AUTOSAR XML (schema 4-2-2)
package /DBC_SysDesc_Can_Network/Pkg_Cluster
  can cluster Can_Network: protocol-name=CAN
    can physical channel Can_Network_Channel: comm-connectors=Conn_Can_Network_CANNODE_0_MCU
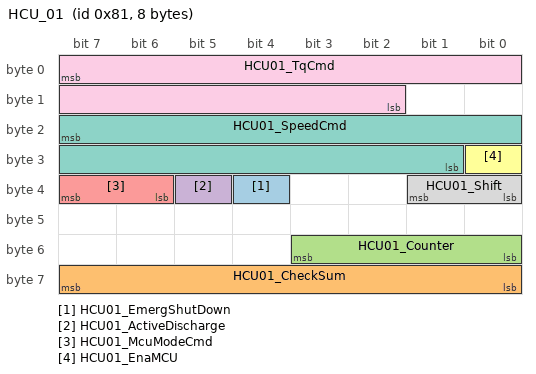
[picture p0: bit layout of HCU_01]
      frame HCU_01: id 0x81, to MCU, frame-length=8, can-addressing-mode=STANDARD, can-frame-rx-behavior=ANY
        carries pdu HCU_01: packing-byte-order=big-endian, start-position=7, update-indication-bit-position=-1
        pdu HCU_01: length=8, transmission-mode-false-timing=cyclic-timing={time-offset=0.0, time-period=0.01}, transmission-mode-true-timing=cyclic-timing={time-offset=0.0, time-period=0.01}
          transmission-mode-conditions:
            {data-filter={data-filter-type=ALWAYS, max=1, min=0, offset=0}, i-signal-in-i-pdu=HCU01_EmergShutDown}
            {data-filter={data-filter-type=ALWAYS, max=255, min=0, offset=0}, i-signal-in-i-pdu=HCU01_CheckSum}
            {data-filter={data-filter-type=ALWAYS, max=15, min=0, offset=0}, i-signal-in-i-pdu=HCU01_Counter}
            {data-filter={data-filter-type=ALWAYS, max=1, min=0, offset=0}, i-signal-in-i-pdu=HCU01_ActiveDischarge}
            {data-filter={data-filter-type=ALWAYS, max=3, min=0, offset=0}, i-signal-in-i-pdu=HCU01_McuModeCmd}
            {data-filter={data-filter-type=ALWAYS, max=1, min=0, offset=0}, i-signal-in-i-pdu=HCU01_EnaMCU}
            {data-filter={data-filter-type=NEW-IS-WITHIN, max=32767, min=0}, i-signal-in-i-pdu=HCU01_SpeedCmd}
            {data-filter={data-filter-type=ALWAYS, max=3, min=0, offset=0}, i-signal-in-i-pdu=HCU01_Shift}
            {data-filter={data-filter-type=NEW-IS-WITHIN, max=16383, min=0}, i-signal-in-i-pdu=HCU01_TqCmd}
          signal HCU01_EmergShutDown: start 36, 1 bit, big-endian, init-value=0, base-type=uint8, compu {raw=phys for phys 0..1, 0=FORBIDDING, 1=ALLOWING}, update-indication-bit-position=-1  # MCUÊ¹ÄÜÐÅºÅ "
          signal HCU01_CheckSum: start 63, 8 bit, big-endian, init-value=0, base-type=uint8, compu {raw=phys for phys 0..255}, update-indication-bit-position=-1, to MCU  # ¼ì²é "
          signal HCU01_Counter: start 51, 4 bit, big-endian, init-value=0, base-type=uint8, compu {raw=phys for phys 0..15}, update-indication-bit-position=-1, to MCU  # ¹öÂëÐÅÏ¢ "
          signal HCU01_ActiveDischarge: start 37, 1 bit, big-endian, init-value=0, base-type=uint8, compu {raw=phys for phys 0..1, 0=FORBIDDING, 1=ALLOWING}, update-indication-bit-position=-1, to MCU  # MCUÖ÷¶¯·Åµç "
          signal HCU01_McuModeCmd: start 39, 2 bit, big-endian, init-value=0, base-type=uint8, compu-method=CompuMethod_HCU01_McuModeCmd, update-indication-bit-position=-1, to MCU  # µç»ú¹¤×÷Ä£Ê½ÇëÇó "
          signal HCU01_EnaMCU: start 24, 1 bit, big-endian, init-value=0, base-type=uint8, compu {raw=phys for phys 0..1, 0=FORBIDDING, 1=ALLOWING}, update-indication-bit-position=-1, to MCU  # MCUÊ¹ÄÜÐÅºÅ "
          signal HCU01_SpeedCmd: start 23, 15 bit, big-endian, init-value=16384, base-type=uint16, compu {raw=phys+16384 for phys -16384..16383; unit rpm}, update-indication-bit-position=-1, to MCU  # ÐèÇó×ªËÙ "
          signal HCU01_Shift: start 33, 2 bit, big-endian, init-value=0, base-type=uint8, compu {raw=phys for phys 0..3, 0=N, 1=R, 2=D, 3=P}, update-indication-bit-position=-1, to MCU  # µ±Ç°Õû³µµµÎ»ÐÅÏ¢ "
          signal HCU01_TqCmd: start 7, 14 bit, big-endian, init-value=8192, base-type=uint16, compu {raw=phys*4+8192 for phys -2048..2047.75; unit Nm}, update-indication-bit-position=-1, to MCU  # HCU¶ÔMCUÅ¤¾ØÇëÇó"
      frame HCU_02: id 0x261, to MCU, frame-length=1, can-addressing-mode=STANDARD, can-frame-rx-behavior=ANY
        carries pdu HCU_02: packing-byte-order=big-endian, start-position=7, update-indication-bit-position=-1
        pdu HCU_02: length=1, transmission-mode-condition{data-filter={data-filter-type=ALWAYS, max=1, min=0, offset=0}, i-signal-in-i-pdu=HCU02_Poweroff}, transmission-mode-false-timing=cyclic-timing={time-offset=0.0, time-period=0.01}, transmission-mode-true-timing=cyclic-timing={time-offset=0.0, time-period=0.01}
          signal HCU02_Poweroff: start 6, 1 bit, big-endian, init-value=0, base-type=uint8, compu {raw=phys for phys 0..1, 0=NORMAL, 1=SLEEP}, update-indication-bit-position=-1, to MCU  # HCUµÍÑ¹ÏÂµç "
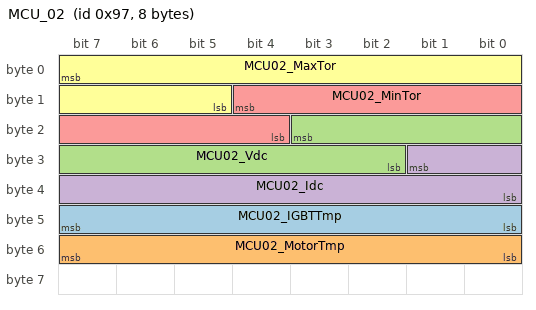
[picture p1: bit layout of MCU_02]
      frame MCU_02: id 0x97, from MCU, frame-length=8, can-addressing-mode=STANDARD
        carries pdu MCU_02: packing-byte-order=big-endian, start-position=7, update-indication-bit-position=-1
        pdu MCU_02: length=8, transmission-mode-false-timing=cyclic-timing={time-offset=0.0, time-period=0.05}, transmission-mode-true-timing=cyclic-timing={time-offset=0.0, time-period=0.05}
          transmission-mode-conditions:
            {data-filter={data-filter-type=ALWAYS, max=254, min=0}, i-signal-in-i-pdu=MCU02_IGBTTmp}
            {data-filter={data-filter-type=ALWAYS, max=254, min=0}, i-signal-in-i-pdu=MCU02_MotorTmp}
            {data-filter={data-filter-type=NEW-IS-WITHIN, max=1022, min=0, offset=0}, i-signal-in-i-pdu=MCU02_Vdc}
            {data-filter={data-filter-type=NEW-IS-WITHIN, max=1022, min=0}, i-signal-in-i-pdu=MCU02_Idc}
            {data-filter={data-filter-type=NEW-IS-WITHIN, max=510, min=0, offset=0}, i-signal-in-i-pdu=MCU02_MinTor}
            {data-filter={data-filter-type=NEW-IS-WITHIN, max=2046, min=0, offset=0}, i-signal-in-i-pdu=MCU02_MaxTor}
          signal MCU02_IGBTTmp: start 47, 8 bit, big-endian, init-value=40, base-type=uint8, compu {raw=phys+40 for phys -40..214; unit deg}, update-indication-bit-position=-1  # IGBTÎÂ¶È "
          signal MCU02_MotorTmp: start 55, 8 bit, big-endian, init-value=40, base-type=uint8, compu {raw=phys+40 for phys -40..214; unit deg}, update-indication-bit-position=-1  # µç»úÎÂ¶È "
          signal MCU02_Vdc: start 19, 10 bit, big-endian, init-value=0, base-type=uint16, compu {raw=phys for phys 0..1022; unit V}, update-indication-bit-position=-1  # Ä¸ÏßµçÑ¹ "
          signal MCU02_Idc: start 25, 10 bit, big-endian, init-value=511, base-type=uint16, compu {raw=phys+511 for phys -511..511; unit Ampere}, update-indication-bit-position=-1  # Ä¸ÏßµçÁ÷ "
          signal MCU02_MinTor: start 12, 9 bit, big-endian, init-value=0, base-type=uint16, compu {raw=phys for phys 0..510; unit Nm}, update-indication-bit-position=-1  # ×îÐ¡Å¤¾Ø "
          signal MCU02_MaxTor: start 7, 11 bit, big-endian, init-value=0, base-type=uint16, compu {raw=phys for phys 0..2046; unit Nm}, update-indication-bit-position=-1  # ×î´óÅ¤¾Ø "
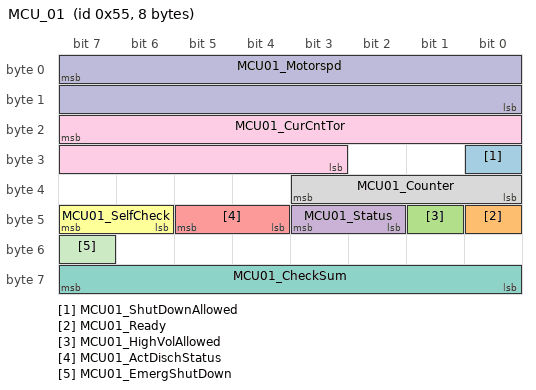
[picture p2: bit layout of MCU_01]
      frame MCU_01: id 0x55, from MCU, frame-length=8, can-addressing-mode=STANDARD
        carries pdu MCU_01: packing-byte-order=big-endian, start-position=7, update-indication-bit-position=-1
        pdu MCU_01: length=8, transmission-mode-false-timing=cyclic-timing={time-offset=0.0, time-period=0.01}, transmission-mode-true-timing=cyclic-timing={time-offset=0.0, time-period=0.01}
          transmission-mode-conditions:
            {data-filter={data-filter-type=ALWAYS, max=1, min=0, offset=0}, i-signal-in-i-pdu=MCU01_ShutDownAllowed}
            {data-filter={data-filter-type=ALWAYS, max=1, min=0, offset=0}, i-signal-in-i-pdu=MCU01_Ready}
            {data-filter={data-filter-type=ALWAYS, max=1, min=0, offset=0}, i-signal-in-i-pdu=MCU01_HighVolAllowed}
            {data-filter={data-filter-type=ALWAYS, max=3, min=0, offset=0}, i-signal-in-i-pdu=MCU01_Status}
            {data-filter={data-filter-type=ALWAYS, max=3, min=0, offset=0}, i-signal-in-i-pdu=MCU01_ActDischStatus}
            {data-filter={data-filter-type=ALWAYS, max=3, min=0, offset=0}, i-signal-in-i-pdu=MCU01_SelfCheck}
            {data-filter={data-filter-type=ALWAYS, max=254, min=0, offset=0}, i-signal-in-i-pdu=MCU01_CheckSum}
            {data-filter={data-filter-type=ALWAYS, max=3, min=0, offset=0}, i-signal-in-i-pdu=MCU01_Counter}
            {data-filter={data-filter-type=NEW-IS-WITHIN, max=8189, min=0}, i-signal-in-i-pdu=MCU01_CurCntTor}
            {data-filter={data-filter-type=NEW-IS-WITHIN, max=65534, min=0}, i-signal-in-i-pdu=MCU01_Motorspd}
            {data-filter={data-filter-type=ALWAYS, max=1, min=0, offset=0}, i-signal-in-i-pdu=MCU01_EmergShutDown}
          signal MCU01_ShutDownAllowed: start 24, 1 bit, big-endian, init-value=0, base-type=uint8, compu {raw=phys for phys 0..1, 0=FORBIDDING, 1=ALLOWING}, update-indication-bit-position=-1  # ÔÊÐíÏÂµç "
          signal MCU01_Ready: start 40, 1 bit, big-endian, init-value=0, base-type=uint8, compu-method=CompuMethod_MCU01_Ready, update-indication-bit-position=-1  # ¸ßÑ¹ÉÏµçÍê³É "
          signal MCU01_HighVolAllowed: start 41, 1 bit, big-endian, init-value=0, base-type=uint8, compu {raw=phys for phys 0..1, 0=FORBIDDINGTOTURNONHV, 1=ALLOWINGTOTURNONHV}, update-indication-bit-position=-1  # ÔÊÐí¸ßÑ¹ÉÏµç "
          signal MCU01_Status: start 43, 2 bit, big-endian, init-value=0, base-type=uint8, compu-method=CompuMethod_MCU01_Status, update-indication-bit-position=-1  # µç»ú¹¤×÷×´Ì¬ "
          signal MCU01_ActDischStatus: start 45, 2 bit, big-endian, init-value=0, base-type=uint8, compu-method=CompuMethod_MCU01_ActDischStatus, update-indication-bit-position=-1  # µç»ú¿ìËÙ·Åµç×´Ì¬ "
          signal MCU01_SelfCheck: start 47, 2 bit, big-endian, init-value=0, base-type=uint8, compu {raw=phys for phys 0..3, 0=DEFAULT, 1=SELFCHECKING, 2=OK, 3=FAILED}, update-indication-bit-position=-1  # MCU×Ô¼ì "
          signal MCU01_CheckSum: start 63, 8 bit, big-endian, init-value=0, base-type=uint8, compu {raw=phys for phys 0..254}, update-indication-bit-position=-1  # ±¨ÎÄchecksum "
          signal MCU01_Counter: start 35, 4 bit, big-endian, init-value=0, base-type=uint8, compu {raw=phys for phys 0..3}, update-indication-bit-position=-1  # ±¨ÎÄ¹öÂëÐÅÏ¢ "
          signal MCU01_CurCntTor: start 23, 13 bit, big-endian, init-value=4094, base-type=uint16, compu {raw=phys*2+4094 for phys -2047..2047.5; unit Nm}, update-indication-bit-position=-1  # µç»úµ±Ç°Å¤¾Ø "
          signal MCU01_Motorspd: start 7, 16 bit, big-endian, init-value=32767, base-type=uint16, compu {raw=phys+32767 for phys -32767..32767; unit rpm}, update-indication-bit-position=-1  # µç»úµ±Ç°×ªËÙ "
          signal MCU01_EmergShutDown: start 55, 1 bit, big-endian, init-value=0, base-type=uint8, compu {raw=phys for phys 0..1, 0=NORMAL, 1=EMERGSHUTDOWN}, update-indication-bit-position=-1  # ½ô¼±ÏÂµçÇëÇó "
      frame MCU_03: id 0x106, from MCU, frame-length=7, can-addressing-mode=STANDARD
        carries pdu MCU_03: packing-byte-order=big-endian, start-position=7, update-indication-bit-position=-1
        pdu MCU_03: length=7, transmission-mode-false-timing=cyclic-timing={time-offset=0.0, time-period=0.05}, transmission-mode-true-timing=cyclic-timing={time-offset=0.0, time-period=0.05}
          transmission-mode-conditions:
            {data-filter={data-filter-type=ALWAYS, max=1, min=0, offset=0}, i-signal-in-i-pdu=MCU03_LI_OverSpeed}
            {data-filter={data-filter-type=ALWAYS, max=1, min=0, offset=0}, i-signal-in-i-pdu=MCU03_LI_OverTempEM}
            {data-filter={data-filter-type=ALWAYS, max=1, min=0, offset=0}, i-signal-in-i-pdu=MCU03_LI_OverTempINV}
            {data-filter={data-filter-type=ALWAYS, max=1, min=0, offset=0}, i-signal-in-i-pdu=MCU03_LI_UdcUnder}
            {data-filter={data-filter-type=ALWAYS, max=1, min=0, offset=0}, i-signal-in-i-pdu=MCU03_LI_UdcOver}
            {data-filter={data-filter-type=ALWAYS, max=1, min=0, offset=0}, i-signal-in-i-pdu=MCU03_RF_PhaseImp}
            {data-filter={data-filter-type=ALWAYS, max=1, min=0, offset=0}, i-signal-in-i-pdu=MCU03_12VSupply}
            {data-filter={data-filter-type=ALWAYS, max=1, min=0, offset=0}, i-signal-in-i-pdu=MCU03_RF_PhCOver}
            {data-filter={data-filter-type=ALWAYS, max=1, min=0, offset=0}, i-signal-in-i-pdu=MCU03_RF_PhBOver}
            {data-filter={data-filter-type=ALWAYS, max=1, min=0, offset=0}, i-signal-in-i-pdu=MCU03_RF_PhAOver}
            {data-filter={data-filter-type=ALWAYS, max=1, min=0, offset=0}, i-signal-in-i-pdu=MCU03_RF_OverSpeed}
            {data-filter={data-filter-type=ALWAYS, max=1, min=0, offset=0}, i-signal-in-i-pdu=MCU03_RF_MsgTO}
            {data-filter={data-filter-type=ALWAYS, max=1, min=0, offset=0}, i-signal-in-i-pdu=MCU03_RF_OverTempEM}
            {data-filter={data-filter-type=ALWAYS, max=1, min=0, offset=0}, i-signal-in-i-pdu=MCU03_RF_OverTempINV}
            {data-filter={data-filter-type=ALWAYS, max=1, min=0, offset=0}, i-signal-in-i-pdu=MCU03_RF_IntError}
            {data-filter={data-filter-type=ALWAYS, max=1, min=0, offset=0}, i-signal-in-i-pdu=MCU03_RF_HWOverCur}
            {data-filter={data-filter-type=ALWAYS, max=1, min=0, offset=0}, i-signal-in-i-pdu=MCU03_RF_UDCUnder}
            {data-filter={data-filter-type=ALWAYS, max=1, min=0, offset=0}, i-signal-in-i-pdu=MCU03_RF_UdcOver}
            {data-filter={data-filter-type=ALWAYS, max=1, min=0, offset=0}, i-signal-in-i-pdu=MCU03_RF_IdcOver}
            {data-filter={data-filter-type=ALWAYS, max=1, min=0, offset=0}, i-signal-in-i-pdu=MCU03_RF_ToqError}
            {data-filter={data-filter-type=ALWAYS, max=1, min=0, offset=0}, i-signal-in-i-pdu=MCU03_RF_BusOff}
            {data-filter={data-filter-type=ALWAYS, max=1, min=0, offset=0}, i-signal-in-i-pdu=MCU03_NRF_SysFailure}
            {data-filter={data-filter-type=ALWAYS, max=1, min=0, offset=0}, i-signal-in-i-pdu=MCU03_NRF_Resolver}
            {data-filter={data-filter-type=ALWAYS, max=1, min=0, offset=0}, i-signal-in-i-pdu=MCU03_NRF_PhCSamp}
            {data-filter={data-filter-type=ALWAYS, max=1, min=0, offset=0}, i-signal-in-i-pdu=MCU03_NRF_PhBSamp}
            {data-filter={data-filter-type=ALWAYS, max=1, min=0, offset=0}, i-signal-in-i-pdu=MCU03_NRF_InvTempSamp}
            {data-filter={data-filter-type=ALWAYS, max=1, min=0, offset=0}, i-signal-in-i-pdu=MCU03_NRF_PhASamp}
            {data-filter={data-filter-type=ALWAYS, max=1, min=0, offset=0}, i-signal-in-i-pdu=MCU03_NRF_DESAT}
            {data-filter={data-filter-type=ALWAYS, max=1, min=0, offset=0}, i-signal-in-i-pdu=MCU03_NRF_UdcSamp}
            {data-filter={data-filter-type=ALWAYS, max=1, min=0, offset=0}, i-signal-in-i-pdu=MCU03_NRF_COMError}
            {data-filter={data-filter-type=ALWAYS, max=1, min=0, offset=0}, i-signal-in-i-pdu=MCU03_NRF_5VSupply}
            {data-filter={data-filter-type=ALWAYS, max=1, min=0, offset=0}, i-signal-in-i-pdu=MCU03_NRF_EMTempSamp}
            {data-filter={data-filter-type=ALWAYS, max=1, min=0, offset=0}, i-signal-in-i-pdu=MCU03_NRF_IdcSamp}
          signal MCU03_LI_OverSpeed: start 51, 1 bit, big-endian, init-value=0, base-type=uint8, compu {raw=phys for phys 0..1, 0=NOTROUBLE, 1=TROUBLE}, update-indication-bit-position=-1  # ³¬ËÙ "
          signal MCU03_LI_OverTempEM: start 50, 1 bit, big-endian, init-value=0, base-type=uint8, compu {raw=phys for phys 0..1, 0=NOTROUBLE, 1=TROUBLE}, update-indication-bit-position=-1  # µç»ú¶¨×Ó¹ýÎÂ "
          signal MCU03_LI_OverTempINV: start 49, 1 bit, big-endian, init-value=0, base-type=uint8, compu {raw=phys for phys 0..1, 0=NOTROUBLE, 1=TROUBLE}, update-indication-bit-position=-1  # Äæ±äÆ÷¹ýÎÂ "
          signal MCU03_LI_UdcUnder: start 48, 1 bit, big-endian, init-value=0, base-type=uint8, compu {raw=phys for phys 0..1, 0=NOTROUBLE, 1=TROUBLE}, update-indication-bit-position=-1  # Ä¸ÏßÇ·Ñ¹ "
          signal MCU03_LI_UdcOver: start 52, 1 bit, big-endian, init-value=0, base-type=uint8, compu {raw=phys for phys 0..1, 0=NOTROUBLE, 1=TROUBLE}, update-indication-bit-position=-1  # Ä¸Ïß¹ýÑ¹ "
          signal MCU03_RF_PhaseImp: start 39, 1 bit, big-endian, init-value=0, base-type=uint8, compu {raw=phys for phys 0..1, 0=NOTROUBLE, 1=TROUBLE}, update-indication-bit-position=-1  # ÈýÏàµçÁ÷²»Æ½ºâ "
          signal MCU03_12VSupply: start 32, 1 bit, big-endian, init-value=0, base-type=uint8, compu {raw=phys for phys 0..1, 0=NOTROUBLE, 1=TROUBLE}, update-indication-bit-position=-1  # ÈõµçµçÔ´¹ÊÕÏ "
          signal MCU03_RF_PhCOver: start 47, 1 bit, big-endian, init-value=0, base-type=uint8, compu {raw=phys for phys 0..1, 0=NOTROUBLE, 1=TROUBLE}, update-indication-bit-position=-1  # CÏà¹ýÁ÷ "
          signal MCU03_RF_PhBOver: start 46, 1 bit, big-endian, init-value=0, base-type=uint8, compu {raw=phys for phys 0..1, 0=NOTROUBLE, 1=TROUBLE}, update-indication-bit-position=-1  # BÏà¹ýÁ÷ "
          signal MCU03_RF_PhAOver: start 45, 1 bit, big-endian, init-value=0, base-type=uint8, compu {raw=phys for phys 0..1, 0=NOTROUBLE, 1=TROUBLE}, update-indication-bit-position=-1  # AÏà¹ýÁ÷ "
          signal MCU03_RF_OverSpeed: start 41, 1 bit, big-endian, init-value=0, base-type=uint8, compu {raw=phys for phys 0..1, 0=NOTROUBLE, 1=TROUBLE}, update-indication-bit-position=-1  # µç»ú¹ýËÙ "
          signal MCU03_RF_MsgTO: start 43, 1 bit, big-endian, init-value=0, base-type=uint8, compu {raw=phys for phys 0..1, 0=NOTROUBLE, 1=TROUBLE}, update-indication-bit-position=-1  # ÏûÏ¢¶ªÊ§ "
          signal MCU03_RF_OverTempEM: start 40, 1 bit, big-endian, init-value=0, base-type=uint8, compu {raw=phys for phys 0..1, 0=NOTROUBLE, 1=TROUBLE}, update-indication-bit-position=-1  # ¶¨×ÓÈÆ×é¹ýÎÂ "
          signal MCU03_RF_OverTempINV: start 36, 1 bit, big-endian, init-value=0, base-type=uint8, compu {raw=phys for phys 0..1, 0=NOTROUBLE, 1=TROUBLE}, update-indication-bit-position=-1  # Äæ±äÆ÷¹ýÎÂ "
          signal MCU03_RF_IntError: start 38, 1 bit, big-endian, init-value=0, base-type=uint8, compu {raw=phys for phys 0..1, 0=NOTROUBLE, 1=TROUBLE}, update-indication-bit-position=-1  # ³ÌÐò³¬Ê± "
          signal MCU03_RF_HWOverCur: start 44, 1 bit, big-endian, init-value=0, base-type=uint8, compu {raw=phys for phys 0..1, 0=NOTROUBLE, 1=TROUBLE}, update-indication-bit-position=-1  # ÏàµçÁ÷Ó²¼þ¼ì²â¹ýÁ÷ "
          signal MCU03_RF_UDCUnder: start 37, 1 bit, big-endian, init-value=0, base-type=uint8, compu {raw=phys for phys 0..1, 0=NOTROUBLE, 1=TROUBLE}, update-indication-bit-position=-1  # Ä¸ÏßÇ·Ñ¹ "
          signal MCU03_RF_UdcOver: start 34, 1 bit, big-endian, init-value=0, base-type=uint8, compu {raw=phys for phys 0..1, 0=NOTROUBLE, 1=TROUBLE}, update-indication-bit-position=-1  # Ä¸Ïß¹ýÑ¹ "
          signal MCU03_RF_IdcOver: start 33, 1 bit, big-endian, init-value=0, base-type=uint8, compu {raw=phys for phys 0..1, 0=NOTROUBLE, 1=TROUBLE}, update-indication-bit-position=-1  # Ä¸Ïß¹ýÁ÷ "
          signal MCU03_RF_ToqError: start 35, 1 bit, big-endian, init-value=0, base-type=uint8, compu {raw=phys for phys 0..1, 0=NOTROUBLE, 1=TROUBLE}, update-indication-bit-position=-1  # Á¦¾ØÊä³öÒì³£ "
          signal MCU03_RF_BusOff: start 42, 1 bit, big-endian, init-value=0, base-type=uint8, compu {raw=phys for phys 0..1, 0=NOTROUBLE, 1=TROUBLE}, update-indication-bit-position=-1  # CAN×ÜÏßÍ¨ÐÅÖÐ¶Ï "
          signal MCU03_NRF_SysFailure: start 11, 1 bit, big-endian, init-value=0, base-type=uint8, compu {raw=phys for phys 0..1, 0=NOTROUBLE, 1=TROUBLE}, update-indication-bit-position=-1  # ÏµÍ³Òì³£ "
          signal MCU03_NRF_Resolver: start 2, 1 bit, big-endian, init-value=0, base-type=uint8, compu {raw=phys for phys 0..1, 0=NOTROUBLE, 1=TROUBLE}, update-indication-bit-position=-1  # Ðý±ä½âÎö¹ÊÕÏ "
          signal MCU03_NRF_PhCSamp: start 5, 1 bit, big-endian, init-value=0, base-type=uint8, compu {raw=phys for phys 0..1, 0=NOTROUBLE, 1=TROUBLE}, update-indication-bit-position=-1  # CÏàµçÁ÷²ÉÑù¹ÊÕÏ "
          signal MCU03_NRF_PhBSamp: start 4, 1 bit, big-endian, init-value=0, base-type=uint8, compu {raw=phys for phys 0..1, 0=NOTROUBLE, 1=TROUBLE}, update-indication-bit-position=-1  # BÏàµçÁ÷²ÉÑù¹ÊÕÏ "
          signal MCU03_NRF_InvTempSamp: start 9, 1 bit, big-endian, init-value=0, base-type=uint8, compu {raw=phys for phys 0..1, 0=NOTROUBLE, 1=TROUBLE}, update-indication-bit-position=-1  # Äæ±äÆ÷ÎÂ¶È²ÉÑù¹ÊÕÏ "
          signal MCU03_NRF_PhASamp: start 3, 1 bit, big-endian, init-value=0, base-type=uint8, compu {raw=phys for phys 0..1, 0=NOTROUBLE, 1=TROUBLE}, update-indication-bit-position=-1  # AÏàµçÁ÷²ÉÑù¹ÊÕÏ "
          signal MCU03_NRF_DESAT: start 0, 1 bit, big-endian, init-value=0, base-type=uint8, compu {raw=phys for phys 0..1, 0=NOTROUBLE, 1=TROUBLE}, update-indication-bit-position=-1  # IGBTÍË±¥ºÍ¹ÊÕÏ "
          signal MCU03_NRF_UdcSamp: start 8, 1 bit, big-endian, init-value=0, base-type=uint8, compu {raw=phys for phys 0..1, 0=NOTROUBLE, 1=TROUBLE}, update-indication-bit-position=-1  # Ä¸ÏßµçÑ¹²ÉÑù¹ÊÕÏ "
          signal MCU03_NRF_COMError: start 10, 1 bit, big-endian, init-value=0, base-type=uint8, compu {raw=phys for phys 0..1, 0=NOTROUBLE, 1=TROUBLE}, update-indication-bit-position=-1  # Í¨Ñ¶Ä£¿é¹ÊÕÏ "
          signal MCU03_NRF_5VSupply: start 1, 1 bit, big-endian, init-value=0, base-type=uint8, compu {raw=phys for phys 0..1, 0=NOTROUBLE, 1=TROUBLE}, update-indication-bit-position=-1  # Ä£Äâ5VµçÔ´¹ÊÕÏ "
          signal MCU03_NRF_EMTempSamp: start 6, 1 bit, big-endian, init-value=0, base-type=uint8, compu {raw=phys for phys 0..1, 0=NOTROUBLE, 1=TROUBLE}, update-indication-bit-position=-1  # µç»úÎÂ¶È²ÉÑù¹ÊÕÏ "
          signal MCU03_NRF_IdcSamp: start 15, 1 bit, big-endian, init-value=0, base-type=uint8, compu {raw=phys for phys 0..1, 0=NOTROUBLE, 1=TROUBLE}, update-indication-bit-position=-1  # Ä¸ÏßµçÁ÷²ÉÑù¹ÊÕÏ "
      frame Diag_Functional_request: id 0x7DF, to MCU, frame-length=8, can-addressing-mode=STANDARD, can-fd-frame-support=true, can-frame-rx-behavior=CAN-FD
        carries pdu Diag_Functional_request: start-position=7, update-indication-bit-position=-1
        dcm i pdu Diag_Functional_request: length=8
      frame Diag_Physical_request: id 0x740, to MCU, frame-length=8, can-addressing-mode=STANDARD, can-fd-frame-support=true, can-frame-rx-behavior=CAN-FD
        carries pdu Diag_Physical_request: start-position=7, update-indication-bit-position=-1
        dcm i pdu Diag_Physical_request: length=8
      frame Diag_Physical_response: id 0x748, from MCU, frame-length=8, can-addressing-mode=STANDARD, can-fd-frame-support=true, can-frame-tx-behavior=CAN-FD
        carries pdu Diag_Physical_response: start-position=7, update-indication-bit-position=-1
        dcm i pdu Diag_Physical_response: length=8
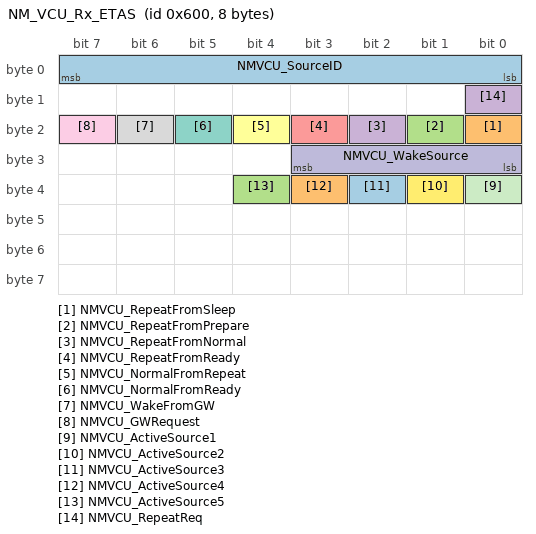
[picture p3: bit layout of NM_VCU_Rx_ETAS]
      frame NM_VCU_Rx_ETAS: id 0x600, to MCU, frame-length=8, can-addressing-mode=STANDARD, can-frame-rx-behavior=ANY
        carries pdu NM_VCU_Rx_ETAS: packing-byte-order=big-endian, start-position=7, update-indication-bit-position=-1
        nm pdu NM_VCU_Rx_ETAS: length=8, nm-data-information=false, nm-vote-information=false
          signal NMVCU_SourceID: start 7, 8 bit, big-endian, init-value=0, base-type=uint8, compu {raw=phys for phys 0..255}, update-indication-bit-position=-1, to MCU  # The source node id"
          signal NMVCU_RepeatFromSleep: start 16, 1 bit, big-endian, init-value=0, base-type=uint8, compu {raw=phys for phys 0..1, 0=NOTOCCUR, 1=OCCUR}, update-indication-bit-position=-1, to MCU
          signal NMVCU_RepeatFromPrepare: start 17, 1 bit, big-endian, init-value=0, base-type=uint8, compu {raw=phys for phys 0..1, 0=NOTOCCUR, 1=OCCUR}, update-indication-bit-position=-1, to MCU
          signal NMVCU_RepeatFromNormal: start 18, 1 bit, big-endian, init-value=0, base-type=uint8, compu {raw=phys for phys 0..1, 0=NOTOCCUR, 1=OCCUR}, update-indication-bit-position=-1, to MCU
          signal NMVCU_RepeatFromReady: start 19, 1 bit, big-endian, init-value=0, base-type=uint8, compu {raw=phys for phys 0..1, 0=NOTOCCUR, 1=OCCUR}, update-indication-bit-position=-1, to MCU
          signal NMVCU_NormalFromRepeat: start 20, 1 bit, big-endian, init-value=0, base-type=uint8, compu {raw=phys for phys 0..1, 0=NOTOCCUR, 1=OCCUR}, update-indication-bit-position=-1, to MCU
          signal NMVCU_NormalFromReady: start 21, 1 bit, big-endian, init-value=0, base-type=uint8, compu {raw=phys for phys 0..1, 0=NOTOCCUR, 1=OCCUR}, update-indication-bit-position=-1, to MCU
          signal NMVCU_WakeFromGW: start 22, 1 bit, big-endian, init-value=0, base-type=uint8, compu {raw=phys for phys 0..1, 0=NOTOCCUR, 1=OCCUR}, update-indication-bit-position=-1, to MCU
          signal NMVCU_GWRequest: start 23, 1 bit, big-endian, init-value=0, base-type=uint8, compu {raw=phys for phys 0..1, 0=NOTREQUEST, 1=REQUEST}, update-indication-bit-position=-1, to MCU
          signal NMVCU_WakeSource: start 27, 4 bit, big-endian, init-value=0, base-type=uint8, compu {raw=phys for phys 0..15, 0=CANWAKEUP, 1=KL_15}, update-indication-bit-position=-1, to MCU  # The wakeup source"
          signal NMVCU_ActiveSource1: start 32, 1 bit, big-endian, init-value=0, base-type=uint8, compu {raw=phys for phys 0..1, 0=NOTACTIVE, 1=KL15}, update-indication-bit-position=-1, to MCU  # The NM active sorce is KL15"
          signal NMVCU_ActiveSource2: start 33, 1 bit, big-endian, init-value=0, base-type=uint8, compu {raw=phys for phys 0..1, 0=NOTACTIVE, 1=DIAGNOSE}, update-indication-bit-position=-1, to MCU  # The NM active sorce is Diagnose"
          signal NMVCU_ActiveSource3: start 34, 1 bit, big-endian, init-value=0, base-type=uint8, compu {raw=phys for phys 0..1, 0=NOTACTIVE, 1=REPEATMESSAGETIMERHASNOTEXPIRED}, update-indication-bit-position=-1, to MCU  # The NM active sorce is Repeat message timer has not expired"
          signal NMVCU_ActiveSource4: start 35, 1 bit, big-endian, init-value=0, base-type=uint8, compu {raw=phys for phys 0..1, 0=NOTACTIVE, 1=ACCHARGING}, update-indication-bit-position=-1, to MCU  # The NM active sorce is AC Charging"
          signal NMVCU_ActiveSource5: start 36, 1 bit, big-endian, init-value=0, base-type=uint8, compu {raw=phys for phys 0..1, 0=NOTACTIVE, 1=DCCHARGING}, update-indication-bit-position=-1, to MCU  # The NM active sorce is DC Charging"
          signal NMVCU_RepeatReq: start 8, 1 bit, big-endian, init-value=0, base-type=uint8, compu {raw=phys for phys 0..1, 0=NOTREQUEST, 1=REQUEST}, update-indication-bit-position=-1, to MCU  # The repeat message request"
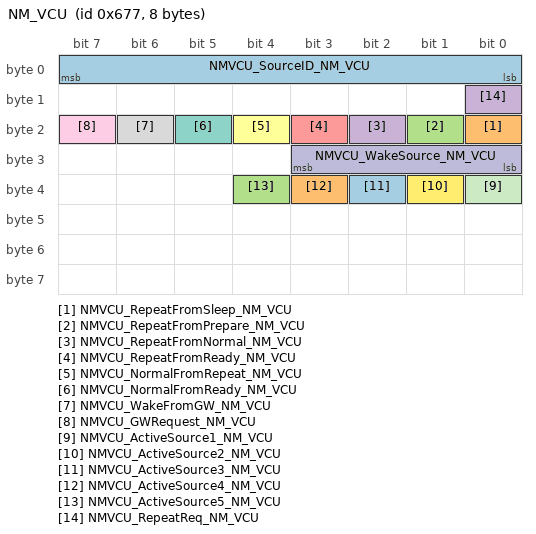
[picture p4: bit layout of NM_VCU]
      frame NM_VCU: id 0x677, from MCU, frame-length=8, can-addressing-mode=STANDARD
        carries pdu NM_VCU: packing-byte-order=big-endian, start-position=7, update-indication-bit-position=-1
        nm pdu NM_VCU: length=8, nm-data-information=false, nm-vote-information=false
          signal NMVCU_SourceID_NM_VCU: start 7, 8 bit, big-endian, init-value=0, base-type=uint8, compu {raw=phys for phys 0..255}, update-indication-bit-position=-1  # The source node id"
          signal NMVCU_RepeatFromSleep_NM_VCU: start 16, 1 bit, big-endian, init-value=0, base-type=uint8, compu {raw=phys for phys 0..1, 0=NOTOCCUR, 1=OCCUR}, update-indication-bit-position=-1
          signal NMVCU_RepeatFromPrepare_NM_VCU: start 17, 1 bit, big-endian, init-value=0, base-type=uint8, compu {raw=phys for phys 0..1, 0=NOTOCCUR, 1=OCCUR}, update-indication-bit-position=-1
          signal NMVCU_RepeatFromNormal_NM_VCU: start 18, 1 bit, big-endian, init-value=0, base-type=uint8, compu {raw=phys for phys 0..1, 0=NOTOCCUR, 1=OCCUR}, update-indication-bit-position=-1
          signal NMVCU_RepeatFromReady_NM_VCU: start 19, 1 bit, big-endian, init-value=0, base-type=uint8, compu {raw=phys for phys 0..1, 0=NOTOCCUR, 1=OCCUR}, update-indication-bit-position=-1
          signal NMVCU_NormalFromRepeat_NM_VCU: start 20, 1 bit, big-endian, init-value=0, base-type=uint8, compu {raw=phys for phys 0..1, 0=NOTOCCUR, 1=OCCUR}, update-indication-bit-position=-1
          signal NMVCU_NormalFromReady_NM_VCU: start 21, 1 bit, big-endian, init-value=0, base-type=uint8, compu {raw=phys for phys 0..1, 0=NOTOCCUR, 1=OCCUR}, update-indication-bit-position=-1
          signal NMVCU_WakeFromGW_NM_VCU: start 22, 1 bit, big-endian, init-value=0, base-type=uint8, compu {raw=phys for phys 0..1, 0=NOTOCCUR, 1=OCCUR}, update-indication-bit-position=-1
          signal NMVCU_GWRequest_NM_VCU: start 23, 1 bit, big-endian, init-value=0, base-type=uint8, compu {raw=phys for phys 0..1, 0=NOTREQUEST, 1=REQUEST}, update-indication-bit-position=-1
          signal NMVCU_WakeSource_NM_VCU: start 27, 4 bit, big-endian, init-value=0, base-type=uint8, compu {raw=phys for phys 0..15, 0=CANWAKEUP, 1=KL_15}, update-indication-bit-position=-1  # The wakeup source"
          signal NMVCU_ActiveSource1_NM_VCU: start 32, 1 bit, big-endian, init-value=0, base-type=uint8, compu {raw=phys for phys 0..1, 0=NOTACTIVE, 1=KL15}, update-indication-bit-position=-1  # The NM active sorce is KL15"
          signal NMVCU_ActiveSource2_NM_VCU: start 33, 1 bit, big-endian, init-value=0, base-type=uint8, compu {raw=phys for phys 0..1, 0=NOTACTIVE, 1=DIAGNOSE}, update-indication-bit-position=-1  # The NM active sorce is Diagnose"
          signal NMVCU_ActiveSource3_NM_VCU: start 34, 1 bit, big-endian, init-value=0, base-type=uint8, compu {raw=phys for phys 0..1, 0=NOTACTIVE, 1=REPEATMESSAGETIMERHASNOTEXPIRED}, update-indication-bit-position=-1  # The NM active sorce is Repeat message timer has not expired"
          signal NMVCU_ActiveSource4_NM_VCU: start 35, 1 bit, big-endian, init-value=0, base-type=uint8, compu {raw=phys for phys 0..1, 0=NOTACTIVE, 1=ACCHARGING}, update-indication-bit-position=-1  # The NM active sorce is AC Charging"
          signal NMVCU_ActiveSource5_NM_VCU: start 36, 1 bit, big-endian, init-value=0, base-type=uint8, compu {raw=phys for phys 0..1, 0=NOTACTIVE, 1=DCCHARGING}, update-indication-bit-position=-1  # The NM active sorce is DC Charging"
          signal NMVCU_RepeatReq_NM_VCU: start 8, 1 bit, big-endian, init-value=0, base-type=uint8, compu {raw=phys for phys 0..1, 0=NOTREQUEST, 1=REQUEST}, update-indication-bit-position=-1  # The repeat message request"
      frame HCU_03: id 0x266, to MCU, frame-length=1, can-addressing-mode=STANDARD, can-frame-rx-behavior=ANY
        carries pdu HCU_03: packing-byte-order=big-endian, start-position=7, update-indication-bit-position=-1
        pdu HCU_03: length=1, transmission-mode-condition{data-filter={data-filter-type=ALWAYS, max=1, min=0, offset=0}, i-signal-in-i-pdu=HCU03_Poweroff}, transmission-mode-false-timing=cyclic-timing={time-offset=0.0, time-period=0.01}, transmission-mode-true-timing=cyclic-timing={time-offset=0.0, time-period=0.01}
          signal HCU03_Poweroff: start 0, 1 bit, big-endian, init-value=0, base-type=uint8, compu {raw=phys for phys 0..1, 0=NORMAL, 1=SLEEP}, update-indication-bit-position=-1, to MCU  # ghh"
      frame HCU_04: id 0x277, to MCU, frame-length=1, can-addressing-mode=STANDARD, can-frame-rx-behavior=ANY
        carries pdu HCU_04: packing-byte-order=big-endian, start-position=7, update-indication-bit-position=-1
        pdu HCU_04: length=1, transmission-mode-condition{data-filter={data-filter-type=ALWAYS, max=1, min=0, offset=0}, i-signal-in-i-pdu=HCU04_Poweroff}, transmission-mode-false-timing=cyclic-timing={time-offset=0.0, time-period=0.01}, transmission-mode-true-timing=cyclic-timing={time-offset=0.0, time-period=0.01}
          signal HCU04_Poweroff: start 0, 1 bit, big-endian, init-value=0, base-type=uint8, compu {raw=phys for phys 0..1, 0=NORMAL, 1=SLEEP}, update-indication-bit-position=-1, to MCU  # ghh"
      frame HCU_05: id 0x288, to MCU, frame-length=1, can-addressing-mode=STANDARD, can-frame-rx-behavior=ANY
        carries pdu HCU_05: packing-byte-order=big-endian, start-position=7, update-indication-bit-position=-1
        pdu HCU_05: length=1, transmission-mode-condition{data-filter={data-filter-type=ALWAYS, max=1, min=0, offset=0}, i-signal-in-i-pdu=HCU05_Poweroff}, transmission-mode-false-timing=cyclic-timing={time-offset=0.0, time-period=0.01}, transmission-mode-true-timing=cyclic-timing={time-offset=0.0, time-period=0.01}
          signal HCU05_Poweroff: start 0, 1 bit, big-endian, init-value=0, base-type=uint8, compu {raw=phys for phys 0..1, 0=NORMAL, 1=SLEEP}, update-indication-bit-position=-1, to MCU  # ghh"
      frame MCU_04: id 0x108, from MCU, frame-length=8, can-addressing-mode=STANDARD
        carries pdu MCU_04: packing-byte-order=big-endian, start-position=7, update-indication-bit-position=-1
        pdu MCU_04: length=8, transmission-mode-condition{data-filter={data-filter-type=ALWAYS, max=1, min=0, offset=0}, i-signal-in-i-pdu=MCU04_Test}, transmission-mode-false-timing=cyclic-timing={time-offset=0.0, time-period=0.05}, transmission-mode-true-timing=cyclic-timing={time-offset=0.0, time-period=0.05}
          signal MCU04_Test: start 15, 1 bit, big-endian, init-value=0, base-type=uint8, compu {raw=phys for phys 0..1, 0=NOTROUBLE, 1=TROUBLE}, update-indication-bit-position=-1  # Ä¸ÏßµçÁ÷²ÉÑù¹ÊÕÏ "
  can cluster Can_Network_XCP: protocol-name=CAN
    can physical channel Can_Network_XCP_Channel: comm-connectors=Conn_Can_Network_CANNODE_1_MCU
      frame XCP_RX_CMD: id 0x333, to MCU, frame-length=8, can-addressing-mode=STANDARD, can-frame-rx-behavior=ANY
        carries pdu XCP_RX_CMD: start-position=7, update-indication-bit-position=-1
        xcp pdu XCP_RX_CMD: length=8
      frame XCP_TX_RES: id 0x777, from MCU, frame-length=8, can-addressing-mode=STANDARD
        carries pdu XCP_TX_RES: start-position=7, update-indication-bit-position=-1
        xcp pdu XCP_TX_RES: length=8
      frame XCP_RX_Broadcast: id 0x332, to MCU, frame-length=8, can-addressing-mode=STANDARD, can-frame-rx-behavior=ANY
        carries pdu XCP_RX_Broadcast: start-position=7, update-indication-bit-position=-1
        xcp pdu XCP_RX_Broadcast: length=8
      frame XCP_TX_DAQ2: id 0x77A, from MCU, frame-length=8, can-addressing-mode=STANDARD
        carries pdu XCP_TX_DAQ2: start-position=7, update-indication-bit-position=-1
        xcp pdu XCP_TX_DAQ2: length=8
      frame XCP_TX_DAQ1: id 0x779, from MCU, frame-length=8, can-addressing-mode=STANDARD
        carries pdu XCP_TX_DAQ1: start-position=7, update-indication-bit-position=-1
        xcp pdu XCP_TX_DAQ1: length=8
      frame XCP_TX_DAQ0: id 0x778, from MCU, frame-length=8, can-addressing-mode=STANDARD
        carries pdu XCP_TX_DAQ0: start-position=7, update-indication-bit-position=-1
        xcp pdu XCP_TX_DAQ0: length=8
package /DBC_SysDesc_Can_Network/Pkg_Ecu
  ecu instance MCU: com-configuration-gw-time-base=0.005, com-configuration-rx-time-base=0.01, com-configuration-tx-time-base=0.01, sleep-mode-supported=false, wake-up-over-bus-supported=false
    can communication controller Can_Network_CANNODE_0: can-controller-attributes=can-controller-configuration={prop-seg=0, sync-jump-width=0, time-seg-1=10, time-seg-2=0}
    can communication controller Can_Network_CANNODE_1: can-controller-attributes=can-controller-configuration={prop-seg=1, sync-jump-width=1, time-seg-1=3, time-seg-2=3}
    can communication connector Conn_Can_Network_CANNODE_0_MCU: comm-controller=Can_Network_CANNODE_0
    can communication connector Conn_Can_Network_CANNODE_1_MCU: comm-controller=Can_Network_CANNODE_1
package /DBC_SysDesc_Can_Network/Pkg_CompuMethod
  compu method CompuMethod_MCU01_Ready: raw=phys for phys 0..1, 0=FORBIDDINGGETTINGTORQUECMD, 1=ALLOWMCUTOGETTORQUECOMMAND
  compu method CompuMethod_MCU01_Status: raw=phys for phys 0..3, 0=NORMAL, 1=WARNING_DERATING, 2=RECOVERABLEFAULT, 3=NORECOVERABLEFAULT
  compu method CompuMethod_MCU01_ActDischStatus: raw=phys for phys 0..3, 0=DEFAULT, 1=DISCHARGING, 2=DISCHARGEFINISHED, 3=RESERVED
  compu method CompuMethod_HCU01_McuModeCmd: raw=phys for phys 0..3, 0=DEFAULT, 1=TORQUEMODE, 2=SPEEDMODE, 3=RESERVED
package /DBC_SysDesc_Can_Network/Pkg_Units
  5 x unit:
    Nm
    rpm
    deg
    Ampere
    V
package /System
  system System: category=SYSTEM_EXTRACT
    system mapping SystemMapping
      data-mappings:
        data-element=CPT_ASW_COM.RootSwCompositionPrototype.PPort_MCU01_EmergShutDown.MCU01_EmergShutDown, system-signal=MCU01_EmergShutDown
        data-element=CPT_ASW_COM.RootSwCompositionPrototype.PPort_MCU02_MaxTor.MCU02_MaxTor, system-signal=MCU02_MaxTor
        data-element=CPT_ASW_COM.RootSwCompositionPrototype.PPort_MCU03_NRF_IdcSamp.MCU03_NRF_IdcSamp, system-signal=MCU03_NRF_IdcSamp
        data-element=CPT_ASW_COM.RootSwCompositionPrototype.RPort_HCU01_Shift.HCU01_Shift, system-signal=HCU01_Shift
        data-element=CPT_ASW_COM.RootSwCompositionPrototype.RPort_HCU01_TqCmd.HCU01_Tq_Cmd, system-signal=HCU01_TqCmd
        data-element=CPT_ASW_COM.RootSwCompositionPrototype.RPort_HCU02_Poweroff.HCU02_Poweroff, system-signal=HCU02_Poweroff
        data-element=CPT_ASW_COM.RootSwCompositionPrototype.RPott_HCU03_Poweroff.HCU03_Poweroff, system-signal=HCU03_Poweroff
        data-element=CPT_ASW_COM.RootSwCompositionPrototype.PPort_MCU04_Test.MCU04_Test, system-signal=MCU04_Test
        data-element=CPT_ASW_COM.RootSwCompositionPrototype.RPort_HCU04_Poweroff.HCU04_Poweroff, system-signal=HCU04_Poweroff
        data-element=CPT_ASW_COM.RootSwCompositionPrototype.RPort_HCU05_Poweroff.HCU05_Poweroff, system-signal=HCU05_Poweroff
      sw-mappings:
        swc to ecu mapping SwcToEcuMapping_0: ecu-instance=MCU
          component:
            RootSwCompositionPrototype.CPT_ASW_BASE
            RootSwCompositionPrototype.CPT_ASW_COM
            RootSwCompositionPrototype.CPT_ASW_NM
            RootSwCompositionPrototype.CPT_ASW_NVM
            RootSwCompositionPrototype.CPT_ASW_WDG
            RootSwCompositionPrototype.CPT_BswM
            RootSwCompositionPrototype.CPT_ComM
            RootSwCompositionPrototype.CPT_Dcm
            RootSwCompositionPrototype.CPT_Dem
            RootSwCompositionPrototype.CPT_Dem_SWC
            RootSwCompositionPrototype.CPT_Det
            RootSwCompositionPrototype.CPT_Diag
            RootSwCompositionPrototype.CPT_EcuM
            RootSwCompositionPrototype.CPT_NvM
            RootSwCompositionPrototype.CPT_Wdg
            RootSwCompositionPrototype.CPT_XCP
            RootSwCompositionPrototype.CPT_ASW_CORE1
            RootSwCompositionPrototype.CPT_ASW_CORE2
    root-software-compositions:
      root sw composition prototype RootSwCompositionPrototype: software-composition=Composition
package /EcucValueCollection
  ecuc value collection EcucValueCollection: ecu-extract=EXTR_MCU, ecuc-values=[OsCfg, RteCfg, BswM, EcuM, Can, CanTp, Dem, Dcm, WdgM, Xcp, Com, CanSM, CanNm, EcuC]
